# RE01_256KB register map
Vendor: Renesas Electronics Corporation; Series: RE01; File version: 1.00.01
CPU: CM0PLUS r0p1, little endian, MPU, no FPU, VTOR, 2 interrupt priority bits, 32 interrupts
Registers are 8-bit, read-write, reset 0x0 unless marked. A register's access mark holds for its fields unless they carry their own. Offsets are from the block's base; [hi:lo] are bit positions; 'fields as' and 'values as' point back to an identical list.

## TMR0 — 8-Bit Timer 0
Base 0x40052000
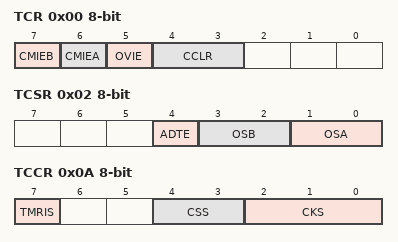
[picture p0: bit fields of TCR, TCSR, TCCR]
0x00 TCR — Timer Control Register
  [7] CMIEB — Compare Match Interrupt Enable B
    0=Disable compare match B interrupt requests (TMR_CMIBn); 1=Enable compare match B interrupt requests (TMR_CMIBn)
  [6] CMIEA — Compare Match Interrupt Enable A
    0=Disable compare match A interrupt requests (TMR_CMIAn); 1=Enable compare match A interrupt requests (TMR_CMIAn)
  [5] OVIE — Timer Overflow Interrupt Enable
    0=Disable overflow interrupt requests (TMR_OVFn); 1=Enable overflow interrupt requests (TMR_OVFn)
  [4:3] CCLR — Counter Clear
    0=Disable clearing; 1=Clear by compare match A; 2=Clear by compare match B; 3=Clear by an external counter reset signal Select an edge or level with the TCCR.TMRIS bit
0x02 TCSR — Timer Control/Status Register
  [4] ADTE — A/D Trigger Enable
    0=Disable A/D conversion start request by compare match A; 1=Enable A/D conversion start request by compare match A
  [3:2] OSB — Output Select B
    0=No change occurs; 1=High-level output; 2=Low-level output; 3=Inverted output (toggled output)
  [1:0] OSA — Output Select A
    values as OSB
0x04 TCORA reset 0xFF — Time Constant Register A
0x06 TCORB reset 0xFF — Time Constant Register B
0x08 TCNT — Timer Counter
0x0A TCCR — Timer Counter Control Register
  [7] TMRIS — Timer Reset Detection Condition Select
    0=Clear on the falling edge of an external counter reset signal; 1=Clear when an external counter reset signal is low level
  [4:3] CSS — Clock Source Select
  [2:0] CKS — Clock Select

## TMR1 — 8-Bit Timer 1
Base 0x40052001
Registers as TMR0; these are added or differ:
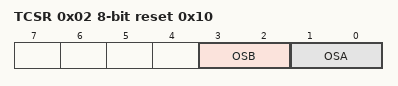
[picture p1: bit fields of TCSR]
0x02 TCSR reset 0x10 — Timer Control/Status Register
  [3:2] OSB — Output Select B
    0=No change occurs; 1=High-level output; 2=Low-level output; 3=Inverted output (toggled output)
  [1:0] OSA — Output Select A
    values as OSB

## DOC — Data Operation Circuit
Base 0x40054100
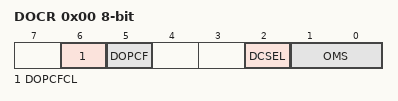
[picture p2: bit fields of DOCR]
0x00 DOCR — DOC Control Register
  [6] DOPCFCL — DOPCF Clear
    0=Retain DOPCF flag state; 1=Clear DOPCF flag
  [5] DOPCF ro — DOC Flag
  [2] DCSEL — Detection Condition Select
    0=Set DOPCF flag when data mismatch is detected; 1=Set DOPCF flag when data match is detected
  [1:0] OMS — Operating Mode Select
    0=Data comparison mode; 1=Data addition mode; 2=Data subtraction mode; 3=Setting prohibited
0x02 DODIR 16-bit — DOC Data Input Register
0x04 DODSR 16-bit — DOC Data Setting Register

## GPT_OPS — Output Phase Switching Controller
Base 0x40055FF0
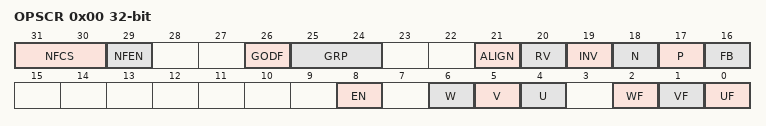
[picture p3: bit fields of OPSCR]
0x00 OPSCR 32-bit — Output Phase Switching Control Register
  [31:30] NFCS — External Input Noise Filter Clock Selection
    0=PCLKA/1; 1=PCLKA/4; 2=PCLKA/16; 3=PCLKA/64
  [29] NFEN — External Input Noise Filter Enable
    0=Do not use a noise filter on the external input; 1=Use a noise filter on the external input
  [26] GODF — Group Output Disable Function
    0=This bit function is ignored; 1=Group disable clears the OPSCR.EN bit
  [25:24] GRP — Output Disabled Source Selection
  [21] ALIGN — Input Phase Alignment
    0=Input phase aligned to PCLKA; 1=Input phase aligned to PWM
  [20] RV — Output Phase Rotation Direction Reversal Control
    0=Positive rotation; 1=Reverse rotation
  [19] INV — Invert-Phase Output Control
    0=Positive logic (active-high) output; 1=Negative logic (active-low) output
  [18] N — Negative-Phase Output (N) Control
    0=Level signal output; 1=PWM signal output (PWM of GPT162)
  [17] P — Positive-Phase Output (P) Control
    0=Level signal output; 1=PWM signal output (PWM of GPT162)
  [16] FB — External Feedback Signal Enable
    0=Select the external input; 1=Select the soft setting (OPSCR.UF, VF, WF)
  [8] EN — Enable-Phase Output Control
    0=Do not output (Hi-Z external pin); 1=Output
  [6] W ro — Input W-Phase Monitor
  [5] V ro — Input V-Phase Monitor
  [4] U ro — Input U-Phase Monitor
  [2] WF
  [1] VF
  [0] UF
